# nrf54h20_engb_sysctrl register map
Vendor: Nordic Semiconductor; Series: nRF54h; File version: 1
Registers are 32-bit, read-write, reset 0x0 unless marked. A register's access mark holds for its fields unless they carry their own. Offsets are from the block's base; [hi:lo] are bit positions; lines under a group give offsets from that group; 'fields as' and 'values as' point back to an identical list.

## FLL16M
Base 0x5F954000
0x00 TASKS_ONESHOTLOCK wo — Start one-shot locking process in Refresh mode.
  [0] TASKS_ONESHOTLOCK
    1=Trigger task
0x04 TASKS_SLEEP wo — Enter into FLL16M sleep mode
  [0] TASKS_SLEEP
    1=Trigger task
0x08 TASKS_FREQMEAS wo — Start frequency measurement in software-controlled mode
  [0] TASKS_FREQMEAS
    1=Trigger task
0x0C TASKS_FREQCHANGE wo — Trigger frequency change
  [0] TASKS_FREQCHANGE
    1=Trigger task
0x100 EVENTS_FREQMDONE — Frequency measurement done
  [0] EVENTS_FREQMDONE
    0=NotGenerated (Event not generated); 1=Generated (Event generated)
0x104 EVENTS_FREQMERROR — Frequency measurement error
  [0] EVENTS_FREQMERROR
    values as EVENTS_FREQMDONE.EVENTS_FREQMDONE
0x108 EVENTS_FREQCHANGED — Frequency change done
  [0] EVENTS_FREQCHANGED
    values as EVENTS_FREQMDONE.EVENTS_FREQMDONE
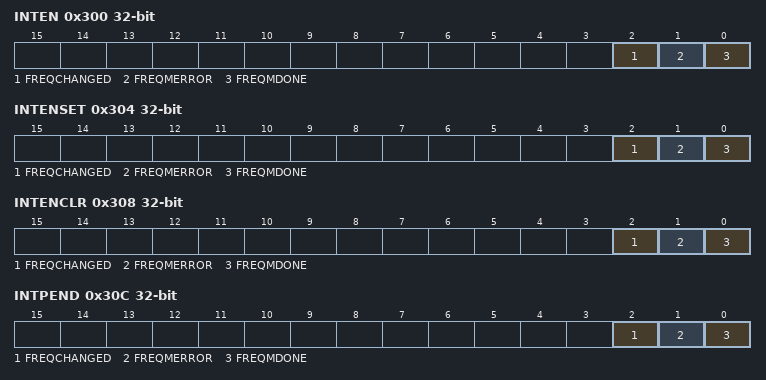
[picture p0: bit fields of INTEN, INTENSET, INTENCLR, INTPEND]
0x300 INTEN — Enable or disable interrupt
  [all] fields
    0=Disabled; 1=Enabled
  [2] FREQCHANGED — Enable or disable interrupt for event FREQCHANGED
  [1] FREQMERROR — Enable or disable interrupt for event FREQMERROR
  [0] FREQMDONE — Enable or disable interrupt for event FREQMDONE
0x304 INTENSET — Enable interrupt
  [all] fields
    on read: 0=Disabled (Read: Disabled); 1=Enabled (Read: Enabled) | on write: 1=Set (Enable)
  [2] FREQCHANGED — Write '1' to enable interrupt for event FREQCHANGED
  [1] FREQMERROR — Write '1' to enable interrupt for event FREQMERROR
  [0] FREQMDONE — Write '1' to enable interrupt for event FREQMDONE
0x308 INTENCLR — Disable interrupt
  [all] fields
    on read: 0=Disabled (Read: Disabled); 1=Enabled (Read: Enabled) | on write: 1=Clear (Disable)
  [2] FREQCHANGED — Write '1' to disable interrupt for event FREQCHANGED
  [1] FREQMERROR — Write '1' to disable interrupt for event FREQMERROR
  [0] FREQMDONE — Write '1' to disable interrupt for event FREQMDONE
0x30C INTPEND ro — Pending interrupts
  [all] fields
    on read: 0=NotPending (Read: Not pending); 1=Pending (Read: Pending)
  [2] FREQCHANGED — Read pending status of interrupt for event FREQCHANGED
  [1] FREQMERROR — Read pending status of interrupt for event FREQMERROR
  [0] FREQMDONE — Read pending status of interrupt for event FREQMDONE
0x400 READY ro — Power up status
  [0] READY — Power up ready.
    0=NotPoweredUp; 1=PoweredUp
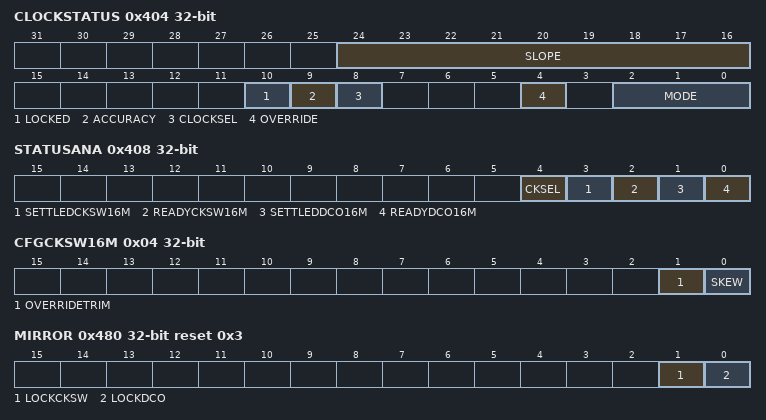
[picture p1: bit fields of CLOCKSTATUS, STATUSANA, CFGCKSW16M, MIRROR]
0x404 CLOCKSTATUS ro
  [24:16] SLOPE — The calculated slope value.
  [10] LOCKED — The FLL16M lock status.
    0=Not locked to reference clock; 1=Locked to reference clock
  [9] ACCURACY — Clock accuracy.
    0=OutsideLimit (Clock accuracy is outside 2 percent.); 1=WithinLimit (Clock accuracy is within 2 percent.)
  [8] CLOCKSEL — Clock selected
    0=DCO16M (Clock from DCO16M selected.); 1=HFXO (Clock from HFXO selected.)
  [4] OVERRIDE — FLL16M Override mode.
    0=Disabled (Override mode disabled.); 1=Enabled (Override mode enabled.)
  [2:0] MODE — The FLL16M operating mode.
    0=Auto (The PCGC controls the mode automatically.); 1=Open loop mode; 2=Closed loop mode; 3=Refresh mode; 4=Bypass mode
0x408 STATUSANA ro — Status of analog module output signals
  [4] CKSEL — Current value of the CKSEL signal from the CKSW16M analog module
  [3] SETTLEDCKSW16M — Current value of the SETTLED signal from the CKSW16M analog module
  [2] READYCKSW16M — Current value of the READY signal from the CKSW16M analog module
  [1] SETTLEDDCO16M — Current value of the SETTLED signal from the DCO16M analog module
  [0] READYDCO16M — Current value of the READY signal from the DCO16M analog module
0x410 CONFIG group — Unspecified
  0x04 CFGCKSW16M — CKSW16M configuration
    [1] OVERRIDETRIM — Enable override trim
      0=Disabled (Override trim is disabled.); 1=Enabled (Override trim is enabled.)
    [0] SKEW — configures the delay used in the phasedetector
      0=SkewNeg56kHz (DCO skew = -56 kHz.); 1=SkewNeg160kHz (DCO skew = -160 kHz.)
0x420 FREQM group — Unspecified
  0x00 DONE ro — Frequency measurement done status
    [0] DONE — Measurement done.
      0=InProgress (Frequency measurement is in progress.); 1=Completed (Frequency measurement is completed.)
  0x04 ERROR ro — Frequency measurement error status
    [0] ERROR — Error status.
      1=OutsideLimit (Frequency exceeded the accuracy 0.5 percent in closed loop mode.); 0=WithinLimit (Frequency stayed within accuracy 0.5 percent in closed loop mode.)
  0x08 MEAS ro — Frequency measurement
    [10:0] VALUE — Last frequency measurement value.
  0x0C CLOCKSEL — Clock select for Frequency measurement
    [1:0] CLOCKSEL — Clock select
      0=DCO16M (Clock from DCO16M selected.); 1=CKSW16M (Clock from CKSW16M selected.); 2=HFXOBy2 (Clock from 32MHz HFXO divided by 2 selected.); 3=CKSW16MTestOsc (Clock from CKSW16M TESTOSC selected.)
0x440 TRIM group — Unspecified
  0x00 RCOARSE — Coarse frequency trimming
    [4:0] VALUE — Coarse frequency trimming value.
  0x04 RFINE — Fine frequency trimming
    [7:0] VALUE — Fine frequency trimming value.
  0x08 TCOEF — Temperature coefficient
    [3:0] VALUE
  0x0C VSUP reset 0x10 — DCO16M internal DCO supply
    [4:0] VALUE
  0x10 CKSW16MTRIM — CKSW16M trim delay
    [3:0] VALUE
0x480 MIRROR reset 0x3 — Enable LOCK for mirrored registers
  [1] LOCKCKSW — Lock for mirrored registers of CKSW
    0=Disabled (Lock disabled); 1=Enabled (Lock enabled)
  [0] LOCKDCO — Lock for mirrored registers of DCO
    0=Disabled (Lock disabled); 1=Enabled (Lock enabled)
0x490 CLOCKCTRL group — Unspecified
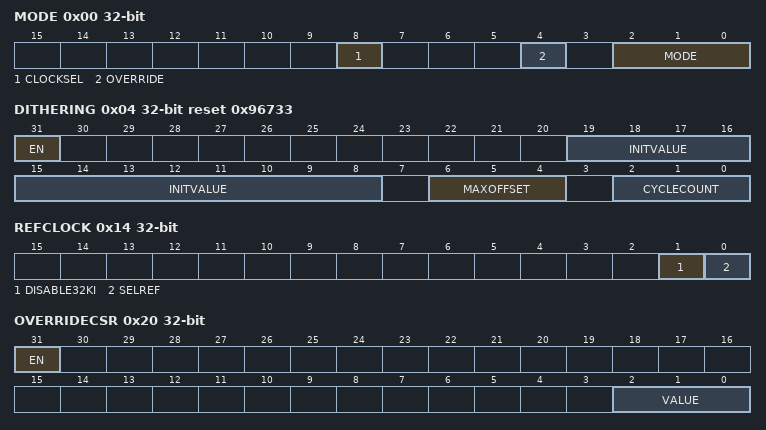
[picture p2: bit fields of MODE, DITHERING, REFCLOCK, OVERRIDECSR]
  0x00 MODE — Clock control
    [8] CLOCKSEL — Clock select
      values as CLOCKSTATUS.CLOCKSEL
    [4] OVERRIDE — FLL16M override mode.
      values as CLOCKSTATUS.OVERRIDE
    [2:0] MODE — The FLL16M operating mode.
      values as CLOCKSTATUS.MODE
  0x04 DITHERING reset 0x96733 — Clock dithering configuration
    [31] EN — Enable the clock dithering
      0=Disabled (Clock dithering is disabled); 1=Enabled (Clock dithering is enabled)
    [19:8] INITVALUE — Initial value for the dithering
    [6:4] MAXOFFSET — Maximum offset configuration for clock dithering
    [2:0] CYCLECOUNT — Cycle count configuration for clock dithering
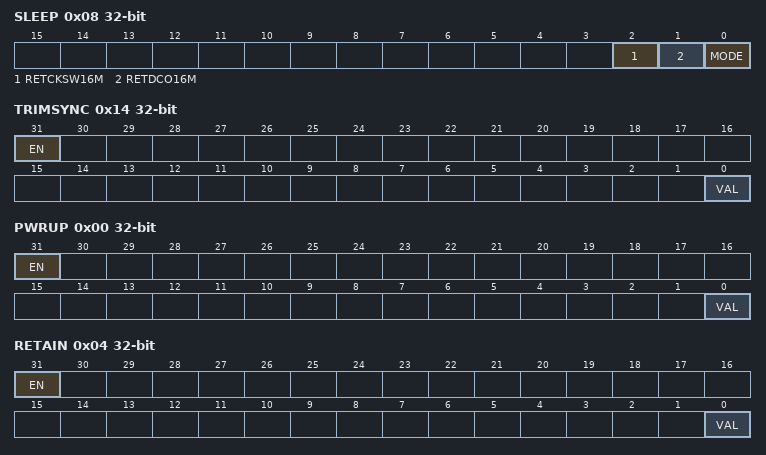
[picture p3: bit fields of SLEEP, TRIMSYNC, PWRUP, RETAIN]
  0x08 SLEEP — Sleep configuration
    [2] RETCKSW16M — Retain CKSW16M.
      0=Disabled (No retention while powered down); 1=Enabled (Retain all inputs while powered down)
    [1] RETDCO16M — Retain DCO16M.
      values as RETCKSW16M
    [0] MODE — FLL16M sleep mode.
      0=Normal mode operation; 1=Sleep (Power down the FLL16M core)
  0x0C RETAINFINETRIM — Fine trim retain control
    [0] RETAIN — Retain control
      0=NoRetain; 1=Retain control when FLL16M goes to open-loop mode
  0x10 OVERRIDELOCKED — Override the LOCKED signal
    [0] OVERRIDE
      0=NoOperation; 1=Override
  0x14 REFCLOCK — Reference clock configuration
    [1] DISABLE32KI — Disable the 32Ki reference clock
      0=Enable (The 32Ki reference clock is enabled); 1=Disable (The 32Ki reference clock is disabled)
    [0] SELREF — Selection for the reference clock signal in software controlled mode
      0=Clock32Ki (The 32Ki clock selected); 1=Clock16M (The 16MHz clock selected)
  0x18 DEFAULTSLOPE reset 0x40 — Default slope value for FLL16M
    [8:0] VALUE — Slope value
  0x1C FREQMEASLIMIT reset 0x2 — Frequency measurement limit
    [2:0] VALUE
  0x20 OVERRIDECSR — Override clockSourceRunning output
    [31] EN — Enable Override
    [2:0] VALUE — Override Value
0x500 OVERRIDE group — Unspecified
  0x00 DCO16M group — Unspecified
    0x00 PWRUP — Override the PWRUP signal to the DCO16M analog module
      [31] EN — Enable the override
        0=Disabled (Override is disabled); 1=Enabled (Override is enabled)
      [0] VAL — Override value for the signal
    0x04 RETAIN — Override the RETAIN signal to the analog module
      fields as OVERRIDE.DCO16M.PWRUP
    0x08 SLEEP — Override the SLEEP signal to the DCO16M analog module
      fields as OVERRIDE.DCO16M.PWRUP
    0x0C READY — Override the DCO16M READY signal from the analog module
      [31] EN — Enable the override
        values as OVERRIDE.DCO16M.PWRUP.EN
      [0] VAL — Current value of the signal
    0x10 SETTLED — Override the DCO16M SETTLED signal from the analog module
      fields as OVERRIDE.DCO16M.READY
    0x14 TRIMSYNC — Override the TRIMSYNC signal to MMI
      fields as OVERRIDE.DCO16M.READY
  0x18 CKSW16M group — Unspecified
    0x00 PWRUP — Override the PWRUP signal to the CKSW16M analog module
      fields as OVERRIDE.DCO16M.PWRUP
    0x04 RETAIN — Override the RETAIN signal to the analog module
      fields as OVERRIDE.DCO16M.PWRUP
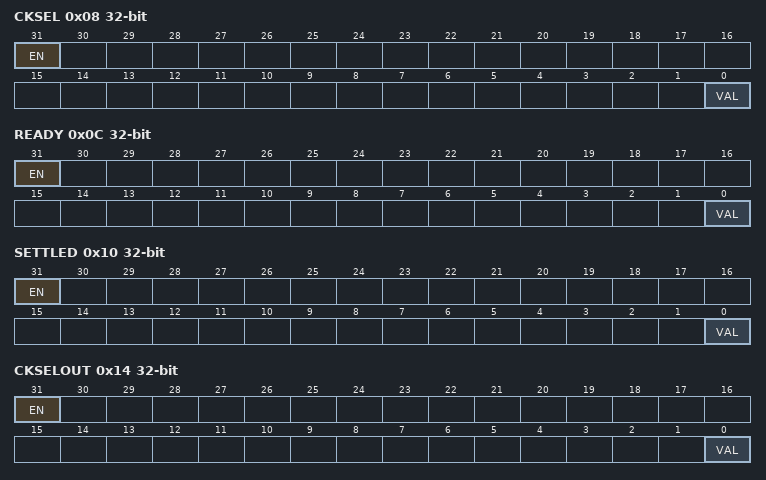
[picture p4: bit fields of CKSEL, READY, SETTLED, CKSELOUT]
    0x08 CKSEL — Override the CKSEL signal to the analog module
      fields as OVERRIDE.DCO16M.PWRUP
    0x0C READY — Override the CKSW16M READY signal from the analog module
      fields as OVERRIDE.DCO16M.READY
    0x10 SETTLED — Override the CKSW16M SETTLED signal from the analog module
      fields as OVERRIDE.DCO16M.READY
    0x14 CKSELOUT — Override the CKSW16M CKSEL signal from the analog module
      fields as OVERRIDE.DCO16M.READY
0x600 DFT group — Unspecified
  0x00 DCO16M group — Unspecified
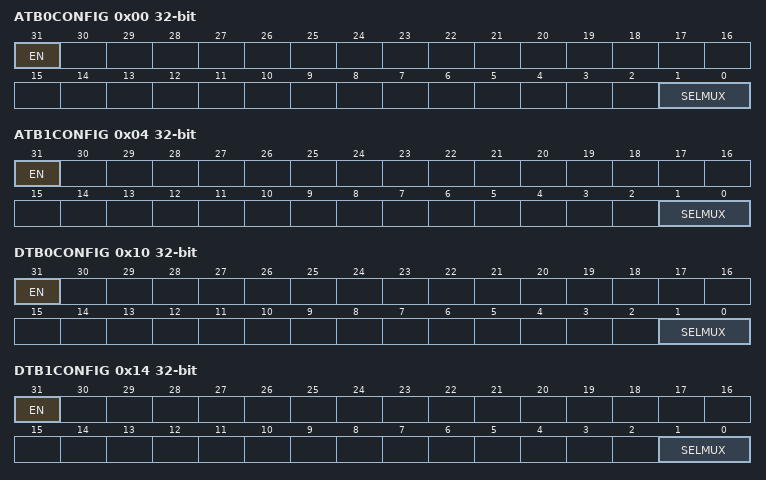
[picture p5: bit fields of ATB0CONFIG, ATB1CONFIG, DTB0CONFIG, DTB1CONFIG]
    0x00 ATB0CONFIG — Analog Test Bus 0 (ATB0) configuration
      [31] EN — Enable the analog test bus
        0=Disabled (Analog test bus is disabled); 1=Enabled (Analog test bus is enabled)
      [1:0] SELMUX — Select multiplexer for ATB0
    0x04 ATB1CONFIG — Analog Test Bus 1 (ATB1) configuration
      [31] EN — Enable the analog test bus
        values as DFT.DCO16M.ATB0CONFIG.EN
      [1:0] SELMUX — Select multiplexer for ATB1
    0x10 DTB0CONFIG — Digital Test Bus 0 (DTB0) configuration
      [31] EN — Enable the digital test bus
        0=Disabled (Digital test bus is disabled); 1=Enabled (Digital test bus is enabled)
      [1:0] SELMUX — Select multiplexer for DTB0
        0=VSS (VSS selected); 1=OSCDIV32INT (OSC_DIV32_INT_0V8 selected); 2=SETTLEDDCO16M (SETTLED_DCO16M_AO_0V8 selected); 3=PWRUPDCO16M (PWRUP_DCO16M_AO_0V8 selected)
    0x14 DTB1CONFIG — Digital Test Bus 1 (DTB1) configuration
      [31] EN — Enable the digital test bus
        values as DFT.DCO16M.DTB0CONFIG.EN
      [1:0] SELMUX — Select multiplexer for DTB1
        0=VSS (VSS selected); 1=RETAINDCO16M (RETAIN_DCO16M_AO_0V8 selected); 2=SETTLEDDCO16M (SETTLED_DCO16M_AO_0V8 selected); 3=OSCDCO16M (OSC_DCO16M_0V8 selected)
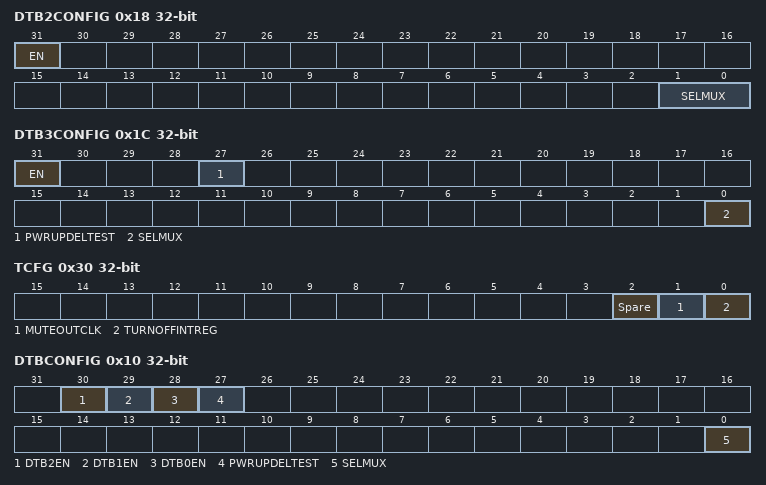
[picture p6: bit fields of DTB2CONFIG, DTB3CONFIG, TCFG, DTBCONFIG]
    0x18 DTB2CONFIG — Digital Test Bus 2 (DTB2) configuration
      [31] EN — Enable the digital test bus
        values as DFT.DCO16M.DTB0CONFIG.EN
      [1:0] SELMUX — Select multiplexer for DTB2
        0=VSS (VSS selected); 1=SETTLEDDCO16M (SETTLED_DCO16M_AO_0V8 selected); 2=READYDCO16M (READY_DCO16M_AO_0V8 selected); 3=OSCDIV16INT (OSC_DIV16_INT_0V8 selected)
    0x1C DTB3CONFIG — Digital Test Bus 3 (DTB3) configuration
      [31] EN — Enable the digital test bus
        values as DFT.DCO16M.DTB0CONFIG.EN
      [27] PWRUPDELTEST — Enable the PWRUP delay test circuit
        0=Disabled (PWRUP delay test circuit is disabled); 1=Enabled (PWRUP delay test circuit is enabled)
      [0] SELMUX — Select multiplexer for DTB3
        0=VSS (VSS selected); 1=SETTLEDDCO16M (SETTLED_DCO16M_AO_0V8 selected)
    0x30 TCFG — Test mode configuration
      [all] fields
        0=Disabled (Unspecified); 1=Enabled (Unspecified)
      [2] Spare
      [1] MUTEOUTCLK — Mute output clock
      [0] TURNOFFINTREG — Turn off internal regulator
  0x40 CKSW16M group — Unspecified
    0x10 DTBCONFIG — Digital Test Bus configuration
      [30] DTB2EN — Enable digital test bus 2
        values as DFT.DCO16M.DTB0CONFIG.EN
      [29] DTB1EN — Enable digital test bus 1
        values as DFT.DCO16M.DTB0CONFIG.EN
      [28] DTB0EN — Enable digital test bus 0
        values as DFT.DCO16M.DTB0CONFIG.EN
      [27] PWRUPDELTEST — Enable the PWRUP delay test circuit
        values as DFT.DCO16M.DTB3CONFIG.PWRUPDELTEST
      [0] SELMUX — Select multiplexer for DTB
        0=DTBSel0 (DTB select 0); 1=DTBSel1 (DTB select 1)
    0x30 TCFG — Test mode configuration
      [1:0] TESTMODE
        0=None (No test mode enabled); 1=CtrlClkMux (Override controller to control clock mux enabled); 2=DelayCells64 (Configure delay cells in phase detector as ring oscillator for characterization, frequency is divided down with a factor of 64); 3=DelayCells128 (Configure delay cells in phase detector as ring oscillator for characterization, frequency is divided down with a factor of 128)
